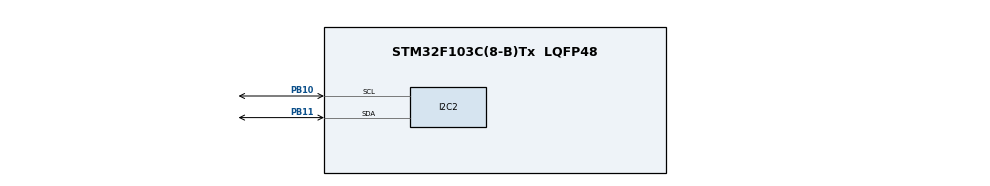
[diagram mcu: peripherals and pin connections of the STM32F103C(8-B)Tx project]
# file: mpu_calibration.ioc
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I2C2.I2C_Mode=I2C_Fast
Mcu.Family=STM32F1
Mcu.Name=STM32F103C(8-B)Tx
Mcu.Package=LQFP48
NVIC.PriorityGroup=NVIC_PRIORITYGROUP_4
PB10.Mode=I2C
PB10.Signal=I2C2_SCL
PB11.Mode=I2C
PB11.Signal=I2C2_SDA
ProjectManager.HeapSize=0x200
ProjectManager.StackSize=0x400
ProjectManager.TargetToolchain=STM32CubeIDE
RCC.APB1Freq_Value=8000000
RCC.APB2Freq_Value=8000000
TIM1.Period=0xffff-1
TIM1.Prescaler=7
VP_SYS_VS_ND.Mode=No_Debug
VP_TIM1_VS_ClockSourceINT.Mode=Internal
board=custom

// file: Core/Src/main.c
/* USER CODE BEGIN Header */
/**
  ******************************************************************************
  * @file           : main.c
  * @brief          : Main program body
  ******************************************************************************
  * @attention
  *
  * Copyright (c) 2024 STMicroelectronics.
  * All rights reserved.
  *
  * This software is licensed under terms that can be found in the LICENSE file
  * in the root directory of this software component.
  * If no LICENSE file comes with this software, it is provided AS-IS.
  *
  ******************************************************************************
  */
/* USER CODE END Header */
#include "main.h"

/* USER CODE BEGIN Includes */
#include <stdio.h>
#include "mpu9255.h"
/* USER CODE END Includes */

I2C_HandleTypeDef hi2c2;

TIM_HandleTypeDef htim1;

/* USER CODE BEGIN PV */
MPU9255_t MPU9255;
/* USER CODE END PV */

void SystemClock_Config(void);
static void MX_GPIO_Init(void);
static void MX_I2C2_Init(void);
static void MX_TIM1_Init(void);

/* USER CODE BEGIN 0 */
int _write(int file, char *ptr, int len)
{
	//HAL_UART_Transmit(&hlpuart1, (uint8_t*)ptr, len, HAL_MAX_DELAY);
	return len;
}

extern float pitch;
extern float yaw;
extern float roll;
extern float magBias[3];
extern float magScale[3];
extern float mx;
extern float my;
extern float mz;
extern int16_t magCount[3];
extern float mRes;
extern float magCalibration[3];
/* USER CODE END 0 */

int main(void)
{

  /* MCU Configuration--------------------------------------------------------*/

  /* Reset of all peripherals, Initializes the Flash interface and the Systick. */
  HAL_Init();

  /* Configure the system clock */
  SystemClock_Config();

  /* Initialize all configured peripherals */
  MX_GPIO_Init();
  MX_I2C2_Init();
  MX_TIM1_Init();
  /* USER CODE BEGIN 2 */
	__HAL_TIM_SET_COUNTER(&htim1, 0);
	HAL_TIM_Base_Start(&htim1);
	calibrateMag(&hi2c2, magBias, magScale);
  /* USER CODE END 2 */

  /* Infinite loop */
  /* USER CODE BEGIN WHILE */
  while (1)
  {

	  //readAll(&hi2c2, &MPU9255);
	  readMagData(&hi2c2, magCount); // Read the x/y/z adc values
	  getMres();

	  // Calculate the magnetometer values in milliGauss
	  // Include factory calibration per data sheet and user environmental corrections
	  mx = (float)magCount[0]*mRes*magCalibration[0] - magBias[0]; // get actual magnetometer value, this depends on scale being set
	  my = (float)magCount[1]*mRes*magCalibration[1] - magBias[1];
	  mz = (float)magCount[2]*mRes*magCalibration[2] - magBias[2];
	  mx *= magScale[0];
	  my *= magScale[1];
	  mz *= magScale[2];

	  MPU9255.MagX = mx;
	  MPU9255.MagY = my;
	  MPU9255.MagZ = mz;

    /* USER CODE END WHILE */

  }
}

void SystemClock_Config(void)
{
  RCC_OscInitTypeDef RCC_OscInitStruct = {0};
  RCC_ClkInitTypeDef RCC_ClkInitStruct = {0};

  /** Initializes the RCC Oscillators according to the specified parameters
  * in the RCC_OscInitTypeDef structure.
  */
  RCC_OscInitStruct.OscillatorType = RCC_OSCILLATORTYPE_HSI;
  RCC_OscInitStruct.HSIState = RCC_HSI_ON;
  RCC_OscInitStruct.HSICalibrationValue = RCC_HSICALIBRATION_DEFAULT;
  RCC_OscInitStruct.PLL.PLLState = RCC_PLL_NONE;
  if (HAL_RCC_OscConfig(&RCC_OscInitStruct) != HAL_OK)
  {
    Error_Handler();
  }

  /** Initializes the CPU, AHB and APB buses clocks
  */
  RCC_ClkInitStruct.ClockType = RCC_CLOCKTYPE_HCLK|RCC_CLOCKTYPE_SYSCLK
                              |RCC_CLOCKTYPE_PCLK1|RCC_CLOCKTYPE_PCLK2;
  RCC_ClkInitStruct.SYSCLKSource = RCC_SYSCLKSOURCE_HSI;
  RCC_ClkInitStruct.AHBCLKDivider = RCC_SYSCLK_DIV1;
  RCC_ClkInitStruct.APB1CLKDivider = RCC_HCLK_DIV1;
  RCC_ClkInitStruct.APB2CLKDivider = RCC_HCLK_DIV1;

  if (HAL_RCC_ClockConfig(&RCC_ClkInitStruct, FLASH_LATENCY_0) != HAL_OK)
  {
    Error_Handler();
  }
}

static void MX_I2C2_Init(void)
{

  hi2c2.Instance = I2C2;
  hi2c2.Init.ClockSpeed = 400000;
  hi2c2.Init.DutyCycle = I2C_DUTYCYCLE_2;
  hi2c2.Init.OwnAddress1 = 0;
  hi2c2.Init.AddressingMode = I2C_ADDRESSINGMODE_7BIT;
  hi2c2.Init.DualAddressMode = I2C_DUALADDRESS_DISABLE;
  hi2c2.Init.OwnAddress2 = 0;
  hi2c2.Init.GeneralCallMode = I2C_GENERALCALL_DISABLE;
  hi2c2.Init.NoStretchMode = I2C_NOSTRETCH_DISABLE;
  if (HAL_I2C_Init(&hi2c2) != HAL_OK)
  {
    Error_Handler();
  }

}

static void MX_TIM1_Init(void)
{

  TIM_ClockConfigTypeDef sClockSourceConfig = {0};
  TIM_MasterConfigTypeDef sMasterConfig = {0};

  htim1.Instance = TIM1;
  htim1.Init.Prescaler = 7;
  htim1.Init.CounterMode = TIM_COUNTERMODE_UP;
  htim1.Init.Period = 0xffff-1;
  htim1.Init.ClockDivision = TIM_CLOCKDIVISION_DIV1;
  htim1.Init.RepetitionCounter = 0;
  htim1.Init.AutoReloadPreload = TIM_AUTORELOAD_PRELOAD_DISABLE;
  if (HAL_TIM_Base_Init(&htim1) != HAL_OK)
  {
    Error_Handler();
  }
  sClockSourceConfig.ClockSource = TIM_CLOCKSOURCE_INTERNAL;
  if (HAL_TIM_ConfigClockSource(&htim1, &sClockSourceConfig) != HAL_OK)
  {
    Error_Handler();
  }
  sMasterConfig.MasterOutputTrigger = TIM_TRGO_RESET;
  sMasterConfig.MasterSlaveMode = TIM_MASTERSLAVEMODE_DISABLE;
  if (HAL_TIMEx_MasterConfigSynchronization(&htim1, &sMasterConfig) != HAL_OK)
  {
    Error_Handler();
  }

}

static void MX_GPIO_Init(void)
{

  /* GPIO Ports Clock Enable */
  __HAL_RCC_GPIOB_CLK_ENABLE();

}

void Error_Handler(void)
{
  __disable_irq();
  while (1)
  {
  }
}
